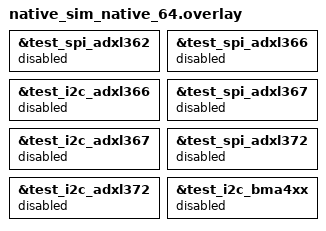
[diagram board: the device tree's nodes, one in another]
/*
 * Copyright (c) 2025 TiaC Systems
 *
 * SPDX-License-Identifier: Apache-2.0
 *
 * Snipped overlay for testing driver builds
 *
 * Names in this file should be chosen in a way that won't conflict
 * with real-world devicetree nodes, to allow these tests to run on
 * (and be extended to test) real hardware.
 */

&test_spi_adxl362 {
	status = "disabled";
};

&test_spi_adxl366 {
	status = "disabled";
};

&test_i2c_adxl366 {
	status = "disabled";
};

&test_spi_adxl367 {
	status = "disabled";
};

&test_i2c_adxl367 {
	status = "disabled";
};

&test_spi_adxl372 {
	status = "disabled";
};

&test_i2c_adxl372 {
	status = "disabled";
};

&test_i2c_bma4xx {
	status = "disabled";
};
